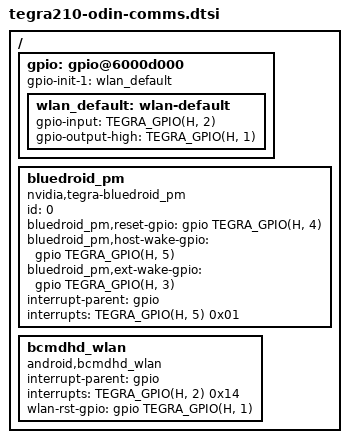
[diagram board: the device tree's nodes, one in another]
/*
 * Copyright (c) 2015, NVIDIA CORPORATION.  All rights reserved.
 *
 * This program is free software; you can redistribute it and/or modify
 * it under the terms of the GNU General Public License as published by
 * the Free Software Foundation; version 2 of the License.
 *
 * This program is distributed in the hope that it will be useful, but WITHOUT
 * ANY WARRANTY; without even the implied warranty of MERCHANTABILITY or
 * FITNESS FOR A PARTICULAR PURPOSE.  See the GNU General Public License for
 * more details.
 */

#include <dt-bindings/gpio/tegra-gpio.h>

/ {
	gpio: gpio@6000d000 {
		gpio-init-1 = <&wlan_default>;

		wlan_default: wlan-default {
			gpio-input = <
				TEGRA_GPIO(H, 2)
				>;
			gpio-output-high = <
				TEGRA_GPIO(H, 1)
				>;
		};
	};

	bluedroid_pm {
		compatible = "nvidia,tegra-bluedroid_pm";
		id = <0>;
		bluedroid_pm,reset-gpio = <&gpio TEGRA_GPIO(H, 4) 0>;
		bluedroid_pm,host-wake-gpio = <&gpio TEGRA_GPIO(H, 5) 0>;
		bluedroid_pm,ext-wake-gpio = <&gpio TEGRA_GPIO(H, 3) 0>;
		interrupt-parent = <&gpio>;
		interrupts = <TEGRA_GPIO(H, 5) 0x01>;
	};

	bcmdhd_wlan {
		compatible = "android,bcmdhd_wlan";
		interrupt-parent = <&gpio>;
		interrupts = <TEGRA_GPIO(H, 2) 0x14>;
		wlan-rst-gpio = <&gpio TEGRA_GPIO(H, 1) 0>;
		status = "okay";
	};
};
